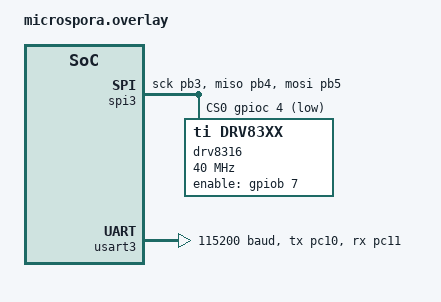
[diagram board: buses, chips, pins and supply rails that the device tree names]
/ {
	chosen {
		zephyr,console = &usart3;
	};

	aliases {
		driver0 = &drv8316;
	};

};

&dma1 {
	status = "okay";
};

&dmamux1 {
	status = "okay";
};


&spi3 {
	dmas = <&dmamux1 2 15 (STM32_DMA_PERIPH_TX | STM32_DMA_PRIORITY_HIGH)>,
	       <&dmamux1 3 14 (STM32_DMA_PERIPH_RX | STM32_DMA_PRIORITY_HIGH)>;
	dma-names = "tx", "rx";
	pinctrl-0 = <&spi3_sck_pb3 &spi3_miso_pb4 &spi3_mosi_pb5>;
	pinctrl-names = "default";
	cs-gpios = <&gpioc 4 (GPIO_ACTIVE_LOW | GPIO_PULL_UP)>;
	status = "okay";

	drv8316: drv8316@0 {
		compatible = "ti,drv83xx";
		reg = <0>;
		spi-max-frequency = <DT_FREQ_M(40)>;
		enable-gpios = <&gpiob 7 0>;
		pwm-mode = <0>;
		slew-rate = <3>;
		sdo-mode = <1>;
		csa-gain = <3>;
		pwm-100-duty-frequency = <0>;
		ocp-mode = <0>;
		ocp-level = <0>;
		ocp-retry = <0>;
		ocp-deglitch = <0>;
		recirculation-mode = <0>;
		buck-voltage = <0>;
		buck-current-limit = <0>;
		delay-target = <0>;
		overvoltage-level = <0>;
		overtemperature-report;
		spi-fault-report;
		ocp-cycle-by-cycle;
		buck-enable;
		buck-power-sequencing;
		delay-compensation;
		status = "okay";
	};
};

&usart3 {
	pinctrl-0 = <&usart3_tx_pc10 &usart3_rx_pc11>;
	pinctrl-names = "default";
	current-speed = <115200>;
	status = "okay";
};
